# PIC32MX360F256L register map
Vendor: Microchip
Registers are 32-bit, read-write, reset 0x0 unless marked. A register's access mark holds for its fields unless they carry their own. Addresses are absolute, and some are shared; only a register's first bit layout is shown; [hi:lo] are bit positions; {n}, {i} and the like mark numbered series.

## PCACHE
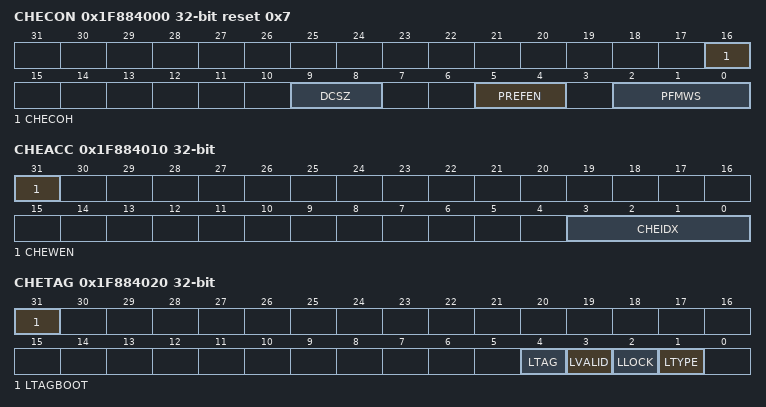
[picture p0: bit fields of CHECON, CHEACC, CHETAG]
0x1F884000 CHECON reset 0x7
  [16] CHECOH, [9:8] DCSZ, [5:4] PREFEN, [2:0] PFMWS
0x1F884010 CHEACC
  [31] CHEWEN, [3:0] CHEIDX
0x1F884020 CHETAG reset not defined — (power-on value 0xxxxxxxxxxxxxxxxxxxxxxxxxxx0010)
  [31] LTAGBOOT, [4] LTAG, [3] LVALID, [2] LLOCK, [1] LTYPE
0x1F884030 CHEMSK
  [15:5] LMASK
{0x1F884040+0x10*i} CHEW{i} reset not defined (i=0..3) — (power-on value xxxxxxxxxxxxxxxxxxxxxxxxxxxxxxxx)
0x1F884080 CHELRU
  [24:0] CHELRU
0x1F884090 CHEHIT reset not defined — (power-on value xxxxxxxxxxxxxxxxxxxxxxxxxxxxxxxx)
  [31:0] CHEHIT — (can only be cleared)
0x1F8840A0 CHEMIS reset not defined — (power-on value xxxxxxxxxxxxxxxxxxxxxxxxxxxxxxxx)
  [31:0] CHEMIS — (can only be cleared)
0x1F8840C0 CHEPFABT reset not defined — (power-on value xxxxxxxxxxxxxxxxxxxxxxxxxxxxxxxx)
  [31:0] CHEPFABT — (can only be cleared)

## YPAA_Ports
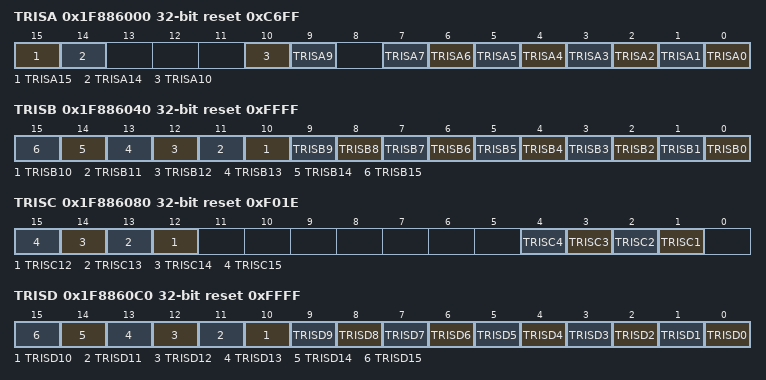
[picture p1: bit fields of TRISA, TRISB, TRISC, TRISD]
0x1F886000 TRISA reset 0xC6FF
  [15] TRISA15, [14] TRISA14, [10] TRISA10, [9] TRISA9, [n] TRISA{n} (n=0..7)
0x1F886040 TRISB reset 0xFFFF
  [n] TRISB{n} (n=0..15)
0x1F886080 TRISC reset 0xF01E
  [n] TRISC{n} (n=12..15), [n] TRISC{n} (n=1..4)
0x1F8860C0 TRISD reset 0xFFFF
  [n] TRISD{n} (n=0..15)
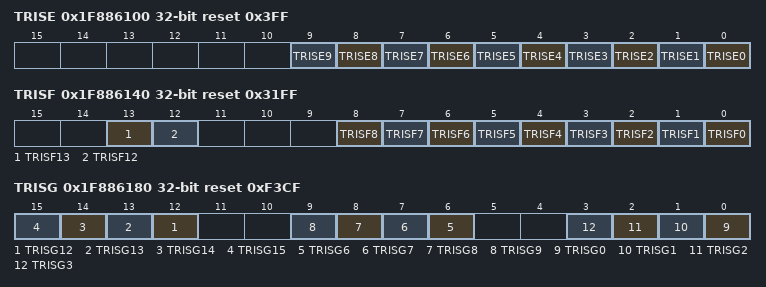
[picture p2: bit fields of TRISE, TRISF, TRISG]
0x1F886100 TRISE reset 0x3FF
  [n] TRISE{n} (n=0..9)
0x1F886140 TRISF reset 0x31FF
  [13] TRISF13, [12] TRISF12, [n] TRISF{n} (n=0..8)
0x1F886180 TRISG reset 0xF3CF
  [n] TRISG{n} (n=12..15), [n] TRISG{n} (n=6..9), [n] TRISG{n} (n=0..3)

## PORTA
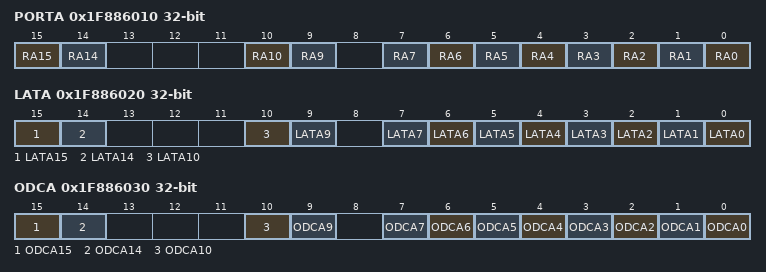
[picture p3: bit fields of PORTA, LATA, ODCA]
0x1F886010 PORTA reset not defined — (power-on value ----------------xx---xx-xxxxxxxx)
  [15] RA15, [14] RA14, [10] RA10, [9] RA9, [n] RA{n} (n=0..7)
0x1F886020 LATA reset not defined — (power-on value ----------------xx---xx-xxxxxxxx)
  [15] LATA15, [14] LATA14, [10] LATA10, [9] LATA9, [n] LATA{n} (n=0..7)
0x1F886030 ODCA
  [15] ODCA15, [14] ODCA14, [10] ODCA10, [9] ODCA9, [n] ODCA{n} (n=0..7)

## PORTB
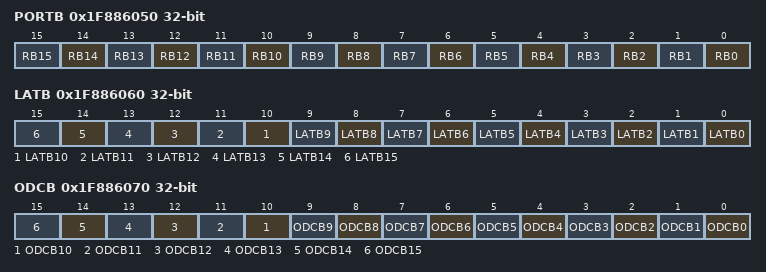
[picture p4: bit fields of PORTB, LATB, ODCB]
0x1F886050 PORTB reset not defined — (power-on value ----------------xxxxxxxxxxxxxxxx)
  [n] RB{n} (n=0..15)
0x1F886060 LATB reset not defined — (power-on value ----------------xxxxxxxxxxxxxxxx)
  [n] LATB{n} (n=0..15)
0x1F886070 ODCB
  [n] ODCB{n} (n=0..15)

## PORTC
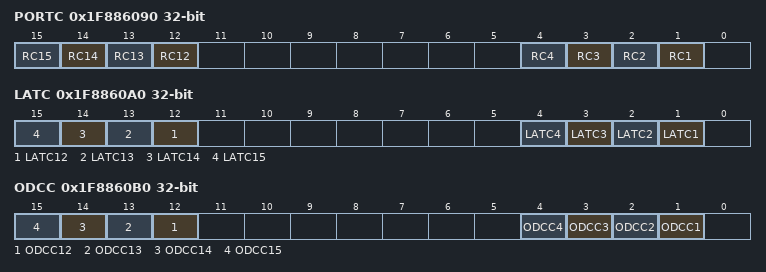
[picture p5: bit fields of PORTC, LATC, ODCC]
0x1F886090 PORTC reset not defined — (power-on value ----------------xxxx-------xxxx-)
  [n] RC{n} (n=12..15), [n] RC{n} (n=1..4)
0x1F8860A0 LATC reset not defined — (power-on value ----------------xxxx-------xxxx-)
  [n] LATC{n} (n=12..15), [n] LATC{n} (n=1..4)
0x1F8860B0 ODCC
  [n] ODCC{n} (n=12..15), [n] ODCC{n} (n=1..4)

## PORTD
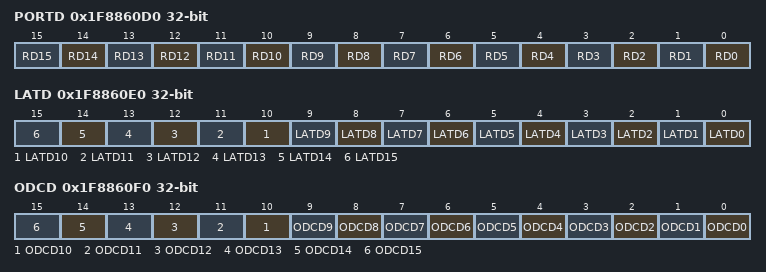
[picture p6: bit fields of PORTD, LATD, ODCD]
0x1F8860D0 PORTD reset not defined — (power-on value ----------------xxxxxxxxxxxxxxxx)
  [n] RD{n} (n=0..15)
0x1F8860E0 LATD reset not defined — (power-on value ----------------xxxxxxxxxxxxxxxx)
  [n] LATD{n} (n=0..15)
0x1F8860F0 ODCD
  [n] ODCD{n} (n=0..15)

## PORTE
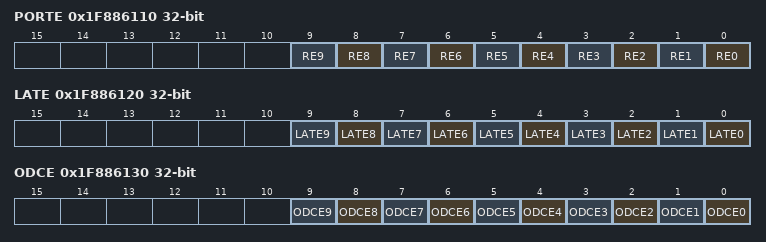
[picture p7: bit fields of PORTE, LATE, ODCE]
0x1F886110 PORTE reset not defined — (power-on value ----------------------xxxxxxxxxx)
  [n] RE{n} (n=0..9)
0x1F886120 LATE reset not defined — (power-on value ----------------------xxxxxxxxxx)
  [n] LATE{n} (n=0..9)
0x1F886130 ODCE
  [n] ODCE{n} (n=0..9)

## PORTF
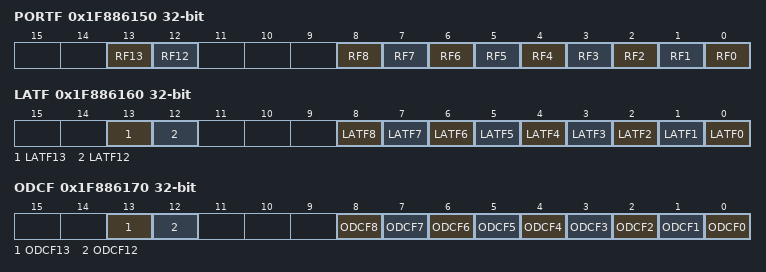
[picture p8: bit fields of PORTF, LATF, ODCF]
0x1F886150 PORTF reset not defined — (power-on value ------------------xx---xxxxxxxxx)
  [13] RF13, [12] RF12, [n] RF{n} (n=0..8)
0x1F886160 LATF reset not defined — (power-on value ------------------xx---xxxxxxxxx)
  [13] LATF13, [12] LATF12, [n] LATF{n} (n=0..8)
0x1F886170 ODCF
  [13] ODCF13, [12] ODCF12, [n] ODCF{n} (n=0..8)

## PORTG
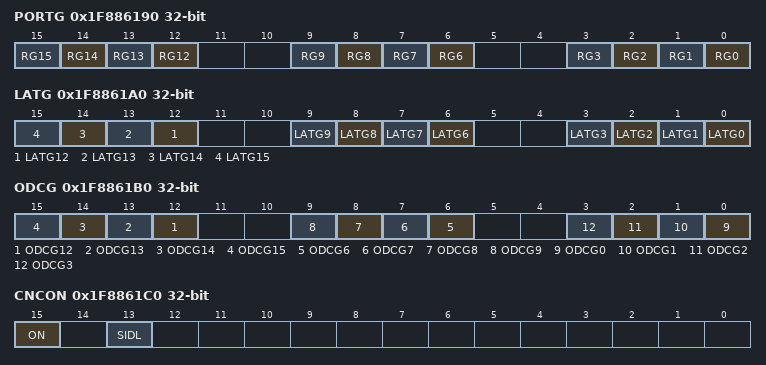
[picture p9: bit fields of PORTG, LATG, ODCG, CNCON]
0x1F886190 PORTG reset not defined — (power-on value ----------------xxxx--xxxx--xxxx)
  [n] RG{n} (n=12..15), [n] RG{n} (n=6..9), [n] RG{n} (n=0..3)
0x1F8861A0 LATG reset not defined — (power-on value ----------------xxxx--xxxx--xxxx)
  [n] LATG{n} (n=12..15), [n] LATG{n} (n=6..9), [n] LATG{n} (n=0..3)
0x1F8861B0 ODCG
  [n] ODCG{n} (n=12..15), [n] ODCG{n} (n=6..9), [n] ODCG{n} (n=0..3)
0x1F8861C0 CNCON
  [15] ON, [13] SIDL
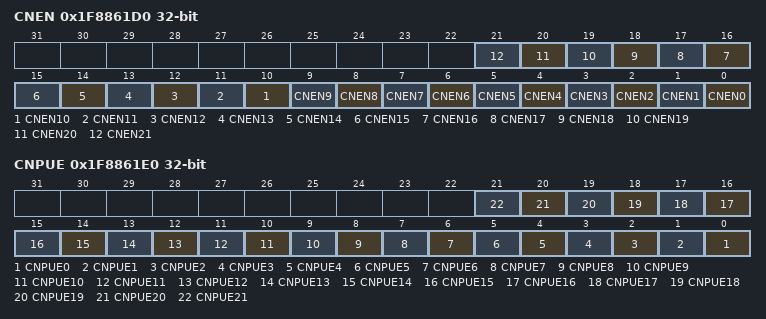
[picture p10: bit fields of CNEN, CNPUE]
0x1F8861D0 CNEN
  [n] CNEN{n} (n=0..21)
0x1F8861E0 CNPUE
  [n] CNPUE{n} (n=0..21)
